VERSION ""

NS_ :

BS_:

BU_:

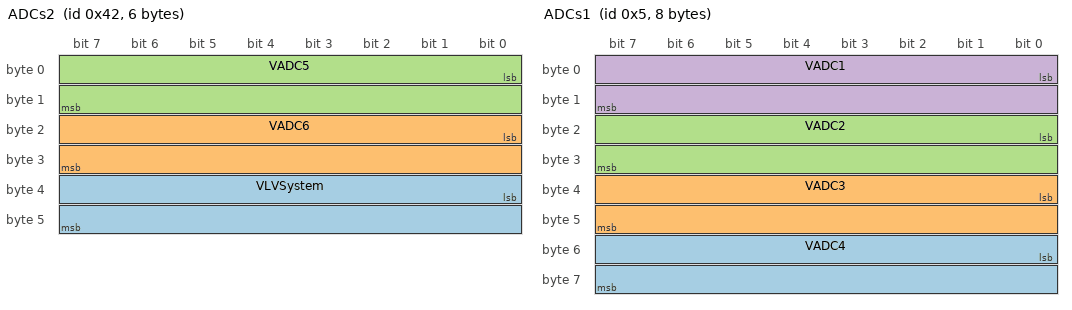
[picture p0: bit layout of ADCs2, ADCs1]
BO_ 66 ADCs2: 6 Vector__XXX
 SG_ VLVSystem : 32|16@1+ (1,0) [0|65535] "" Vector__XXX
 SG_ VADC6 : 16|16@1+ (1,0) [0|65535] "" Vector__XXX
 SG_ VADC5 : 0|16@1+ (1,0) [0|65535] "" Vector__XXX

BO_ 5 ADCs1: 8 Vector__XXX
 SG_ VADC4 : 48|16@1+ (1,0) [0|65535] "" Vector__XXX
 SG_ VADC3 : 32|16@1+ (1,0) [0|65535] "" Vector__XXX
 SG_ VADC2 : 16|16@1+ (1,0) [0|65535] "" Vector__XXX
 SG_ VADC1 : 0|16@1+ (1,0) [0|65535] "" Vector__XXX

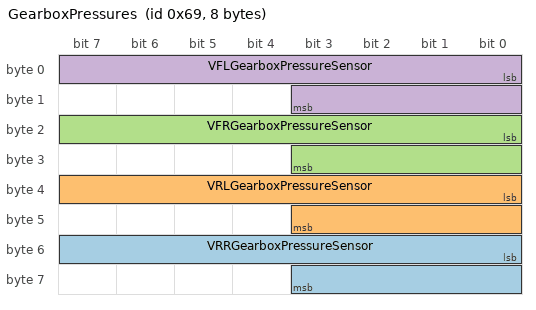
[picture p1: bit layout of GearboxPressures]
BO_ 105 GearboxPressures: 8 Vector__XXX
 SG_ VRRGearboxPressureSensor : 48|12@1+ (1,0) [0|65535] "" Vector__XXX
 SG_ VRLGearboxPressureSensor : 32|12@1+ (1,0) [0|65535] "" Vector__XXX
 SG_ VFRGearboxPressureSensor : 16|12@1+ (1,0) [0|65535] "" Vector__XXX
 SG_ VFLGearboxPressureSensor : 0|12@1+ (1,0) [0|65535] "" Vector__XXX

BA_DEF_  "BusType" STRING ;
BA_DEF_DEF_  "BusType" "CAN";
